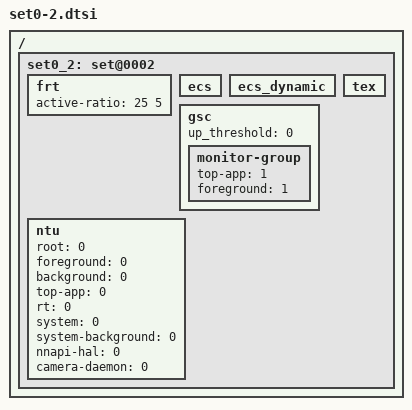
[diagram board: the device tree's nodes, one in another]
/ {
	/* normal mode - app boost */
	set0_2: set@0002 {
		frt {	   			/* LIT BIG */
			active-ratio 		= < 25   5>;
		};

		ecs { };

		ecs_dynamic { };

		tex { };

		gsc {
			up_threshold = <0>;

			monitor-group {
				top-app = <1>;
				foreground = <1>;
			};
		};

		ntu {
			root			= <0>;
			foreground 		= <0>;
			background		= <0>;
			top-app			= <0>;
			rt			= <0>;
			system			= <0>;
			system-background	= <0>;
			nnapi-hal		= <0>;
			camera-daemon		= <0>;
		};
	};
};
